AUTOSAR XML (schema 00051)
package /Components
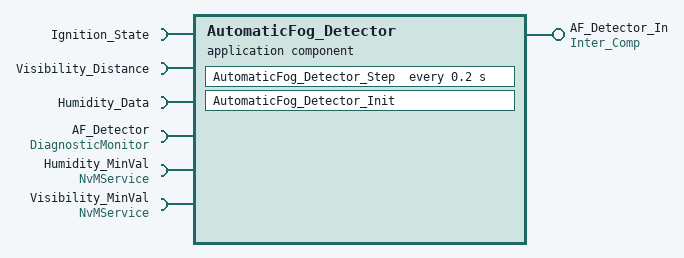
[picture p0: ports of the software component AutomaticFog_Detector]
  application sw component type AutomaticFog_Detector
    require port Ignition_State: nonqueued-receiver-com-spec{data-element=Value, init-value=0}, required-interface=Ignition_State
    require port Visibility_Distance: nonqueued-receiver-com-spec{data-element=Value, init-value=0}, required-interface=Visibility_Distance
    require port Humidity_Data: nonqueued-receiver-com-spec{data-element=Value, init-value=0}, required-interface=Humidity_Data
    provide port AF_Detector_In: nonqueued-sender-com-spec{data-element=Value, init-value=0}, provided-interface=Inter_Comp
    require port AF_Detector: required-interface=DiagnosticMonitor
    require port Humidity_MinVal: required-interface=NvMService
    require port Visibility_MinVal: required-interface=NvMService
    behavior AutomaticFog_Detector_IB: data-type-mapping=dictDataTypeMappingsSet, handle-termination-and-restart=NO-SUPPORT
      timing event Event_AutomaticFog_Detector_Step: start-on-event=AutomaticFog_Detector_Step, period=0.2
      runnable AutomaticFog_Detector_Init
        async call SC_Humidity_MinVal_ReadBlock: operation=Humidity_MinVal.ReadBlock, timeout=1
        async call SC_Visibility_MinVal_ReadBlock: operation=Visibility_MinVal.ReadBlock, timeout=1
      runnable AutomaticFog_Detector_Step
        data-read-access:
          access IN_Visibility_Distance_Value: accessed-variable=Visibility_Distance.Value
          access IN_Humidity_Data_Value: accessed-variable=Humidity_Data.Value
          access IN_Ignition_State_Value: accessed-variable=Ignition_State.Value
        data-write-access:
          access OUT_AF_Detector_In_Value: accessed-variable=AF_Detector_In.Value
        sync call SC_AF_Detector_SetEventStatus: operation=AF_Detector.SetEventStatus, timeout=1.0E-06
